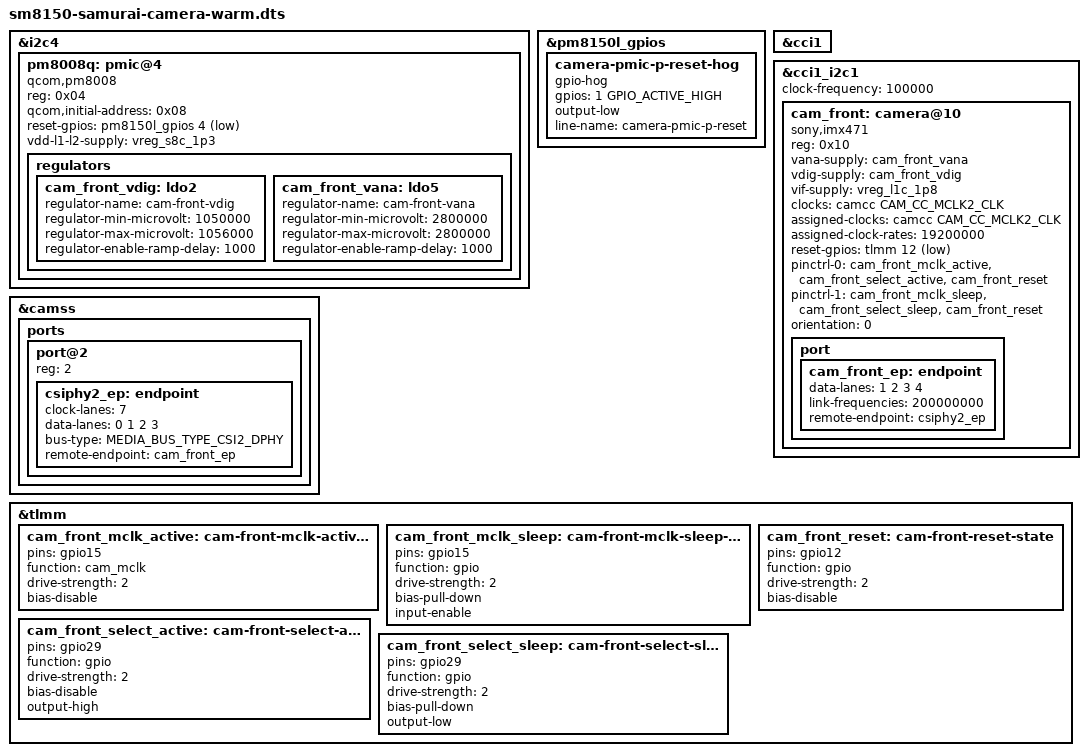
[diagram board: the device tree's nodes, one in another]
// SPDX-License-Identifier: BSD-3-Clause
/*
 * Development candidate for front-camera integration.
 * Q resets to 0x08 and must be assigned 0x04 before releasing sibling P.
 * The four PLDO input nets are NOT described yet.
 * Do not treat this partial PMIC description as an upstream-ready board DTS.
 */
#include "sm8150-samurai.dts"
#include <dt-bindings/media/video-interfaces.h>

&i2c4 {
	pm8008q: pmic@4 {
		compatible = "qcom,pm8008";
		reg = <0x04>;
		qcom,initial-address = <0x08>;
		reset-gpios = <&pm8150l_gpios 4 GPIO_ACTIVE_LOW>;

		/* Only this input is proven; no invented BOB/VPH connections. */
		vdd-l1-l2-supply = <&vreg_s8c_1p3>;

		regulators {
			cam_front_vdig: ldo2 {
				regulator-name = "cam-front-vdig";
				regulator-min-microvolt = <1050000>;
				regulator-max-microvolt = <1056000>;
				regulator-enable-ramp-delay = <1000>;
			};

			cam_front_vana: ldo5 {
				regulator-name = "cam-front-vana";
				regulator-min-microvolt = <2800000>;
				regulator-max-microvolt = <2800000>;
				regulator-enable-ramp-delay = <1000>;
			};
		};
	};
};

&pm8150l_gpios {
	/* Front-only candidate: P must not occupy factory address 0x08. */
	camera-pmic-p-reset-hog {
		gpio-hog;
		gpios = <1 GPIO_ACTIVE_HIGH>;
		output-low;
		line-name = "camera-pmic-p-reset";
	};
};

&cci1 {
	status = "okay";
};

&cci1_i2c1 {
	clock-frequency = <100000>;

	cam_front: camera@10 {
		compatible = "sony,imx471";
		reg = <0x10>;
		vana-supply = <&cam_front_vana>;
		vdig-supply = <&cam_front_vdig>;
		vif-supply = <&vreg_l1c_1p8>;
		clocks = <&camcc CAM_CC_MCLK2_CLK>;
		assigned-clocks = <&camcc CAM_CC_MCLK2_CLK>;
		assigned-clock-rates = <19200000>;
		reset-gpios = <&tlmm 12 GPIO_ACTIVE_LOW>;
		pinctrl-names = "default", "sleep";
		pinctrl-0 = <&cam_front_mclk_active &cam_front_select_active &cam_front_reset>;
		pinctrl-1 = <&cam_front_mclk_sleep &cam_front_select_sleep &cam_front_reset>;
		orientation = <0>;

		port {
			cam_front_ep: endpoint {
				data-lanes = <1 2 3 4>;
				link-frequencies = /bits/ 64 <200000000>;
				remote-endpoint = <&csiphy2_ep>;
			};
		};
	};
};

&camss {
	ports {
		port@2 {
			reg = <2>;

			csiphy2_ep: endpoint {
				clock-lanes = <7>;
				data-lanes = <0 1 2 3>;
				bus-type = <MEDIA_BUS_TYPE_CSI2_DPHY>;
				remote-endpoint = <&cam_front_ep>;
			};
		};
	};
};

&tlmm {
	cam_front_mclk_active: cam-front-mclk-active-state {
		pins = "gpio15";
		function = "cam_mclk";
		drive-strength = <2>;
		bias-disable;
	};

	cam_front_mclk_sleep: cam-front-mclk-sleep-state {
		pins = "gpio15";
		function = "gpio";
		drive-strength = <2>;
		bias-pull-down;
		input-enable;
	};

	cam_front_select_active: cam-front-select-active-state {
		pins = "gpio29";
		function = "gpio";
		drive-strength = <2>;
		bias-disable;
		output-high;
	};

	cam_front_select_sleep: cam-front-select-sleep-state {
		pins = "gpio29";
		function = "gpio";
		drive-strength = <2>;
		bias-pull-down;
		output-low;
	};

	cam_front_reset: cam-front-reset-state {
		pins = "gpio12";
		function = "gpio";
		drive-strength = <2>;
		bias-disable;
	};
};
